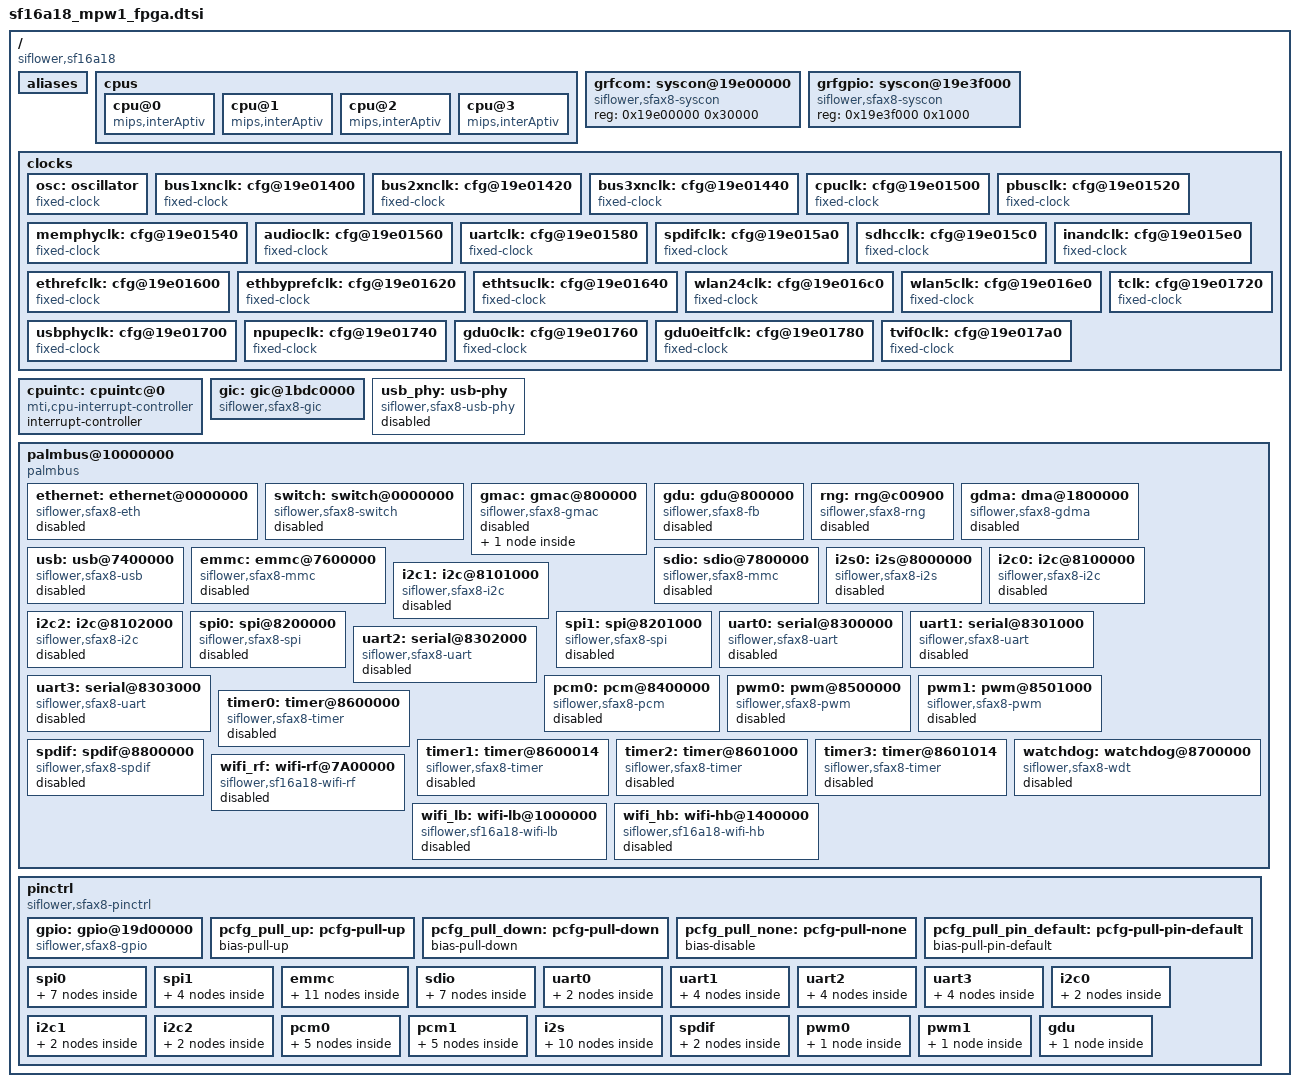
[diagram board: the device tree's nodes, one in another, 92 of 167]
/*
 * This program is free software; you can redistribute it and/or modify
 * it under the terms of the GNU General Public License as published by
 * the Free Software Foundation; either version 2 of the License, or
 * (at your option) any later version.
 *
 * This program is distributed in the hope that it will be useful,
 * but WITHOUT ANY WARRANTY; without even the implied warranty of
 * MERCHANTABILITY or FITNESS FOR A PARTICULAR PURPOSE.  See the
 * GNU General Public License for more details.
 */


/ {
	compatible = "siflower,sf16a18";

	aliases {
		gdu = &gdu;
		gdma = &gdma;
		usb = &usb;
		emmc = &emmc;
		sdio = &sdio;
		i2s = &i2s0;
		i2c0 = &i2c0;
		i2c1 = &i2c1;
		i2c2 = &i2c2;
		spi0 = &spi0;
		spi1 = &spi1;
		uart0=&uart0;
		uart1=&uart1;
		uart2=&uart2;
		uart3=&uart3;
		pcm0 = &pcm0;
		/*pcm1 = &pcm1;*/
		pwm0 = &pwm0;
		pwm1 = &pwm1;
		timer0 = &timer0;
		timer1 = &timer1;
		timer2 = &timer2;
		timer3 = &timer3;
		watchdog = &watchdog;
		spdif = &spdif;
	};

	cpus{
		cpu@0 {
			compatible = "mips,interAptiv";
		};
		cpu@1 {
			compatible = "mips,interAptiv";
		};
		cpu@2 {
			compatible = "mips,interAptiv";
		};
		cpu@3 {
			compatible = "mips,interAptiv";
		};
	};

	grfcom: syscon@19e00000 {
			compatible = "siflower,sfax8-syscon";
			reg = <0x19e00000 0x30000>;
		};

	grfgpio: syscon@19e3f000 {
			compatible = "siflower,sfax8-syscon";
			reg = <0x19e3f000 0x1000>;
		};

	clocks{
		#address-cells = <1>;
		#size-cells = <1>;
		ranges;

		osc: oscillator {
			compatible = "fixed-clock";
			#clock-cells = <0>;
			clock-frequency  = <12000000>;
			clock-output-names = "osc";
		};

		bus1xnclk: cfg@19e01400 {
			compatible = "fixed-clock";
			#clock-cells = <0>;
			clock-frequency  = <50000000>;
			clock-output-names = "bus1xnclk";
		};

		bus2xnclk: cfg@19e01420 {
			compatible = "fixed-clock";
			#clock-cells = <0>;
			clock-frequency  = <50000000>;
			clock-output-names = "bus2xnclk";
		};

		bus3xnclk: cfg@19e01440 {
			compatible = "fixed-clock";
			#clock-cells = <0>;
			clock-frequency  = <80000000>;
			clock-output-names = "bus3xnclk";
		};

		cpuclk: cfg@19e01500 {
			compatible = "fixed-clock";
			#clock-cells = <0>;
			clock-frequency  = <40000000>;
			clock-output-names = "cpuclk";
		};

		pbusclk: cfg@19e01520 {
			compatible = "fixed-clock";
			#clock-cells = <0>;
			clock-frequency  = <50000000>;
			clock-output-names = "pbusclk";
		};

		memphyclk: cfg@19e01540 {
			compatible = "fixed-clock";
			#clock-cells = <0>;
			clock-frequency  = <140000000>;
			clock-output-names = "memphyclk";
		};

		audioclk: cfg@19e01560 {
			compatible = "fixed-clock";
			#clock-cells = <0>;
			clock-frequency  = <60000000>;
			clock-output-names = "audioclk";
		};

		uartclk: cfg@19e01580 {
			compatible = "fixed-clock";
			#clock-cells = <0>;
			clock-frequency  = <60000000>;
			clock-output-names = "uartclk";
		};

		spdifclk: cfg@19e015a0 {
			compatible = "fixed-clock";
			#clock-cells = <0>;
			clock-frequency  = <60000000>;
			clock-output-names = "spdifclk";
		};

		sdhcclk: cfg@19e015c0 {
			compatible = "fixed-clock";
			#clock-cells = <0>;
			clock-frequency  = <50000000>;
			clock-output-names = "sdhcclk";
		};

		inandclk: cfg@19e015e0 {
			compatible = "fixed-clock";
			#clock-cells = <0>;
			clock-frequency  = <50000000>;
			clock-output-names = "inandclk";
		};

		ethrefclk: cfg@19e01600 {
			compatible = "fixed-clock";
			#clock-cells = <0>;
			clock-frequency  = <25000000>;
			clock-output-names = "ethrefclk";
		};

		ethbyprefclk: cfg@19e01620 {
			compatible = "fixed-clock";
			#clock-cells = <0>;
			clock-frequency  = <125000000>;
			clock-output-names = "ethbyprefclk";
		};

		ethtsuclk: cfg@19e01640 {
			compatible = "fixed-clock";
			#clock-cells = <0>;
			clock-frequency  = <25000000>;
			clock-output-names = "ethtsuclk";
		};

		wlan24clk: cfg@19e016c0 {
			compatible = "fixed-clock";
			#clock-cells = <0>;
			clock-frequency  = <30000000>;
			clock-output-names = "wlan24clk";
		};

		wlan5clk: cfg@19e016e0 {
			compatible = "fixed-clock";
			#clock-cells = <0>;
			clock-frequency  = <30000000>;
			clock-output-names = "wlan5clk";
		};

		usbphyclk: cfg@19e01700 {
			compatible = "fixed-clock";
			#clock-cells = <0>;
			clock-frequency  = <50000000>;
			clock-output-names = "usbphyclk";
		};

		tclk: cfg@19e01720 {
			compatible = "fixed-clock";
			#clock-cells = <0>;
			clock-frequency  = <50000000>;
			clock-output-names = "tclk";
		};

		npupeclk: cfg@19e01740 {
			compatible = "fixed-clock";
			#clock-cells = <0>;
			clock-frequency  = <500000000>;
			clock-output-names = "npupeclk";
		};

		gdu0clk: cfg@19e01760 {
			compatible = "fixed-clock";
			#clock-cells = <0>;
			clock-frequency  = <198000000>;
			clock-output-names = "gdu0clk";
		};

		gdu0eitfclk: cfg@19e01780 {
			compatible = "fixed-clock";
			#clock-cells = <0>;
			clock-frequency  = <40000000>;
			clock-output-names = "gdu0eitfclk";
		};

		tvif0clk: cfg@19e017a0 {
			compatible = "fixed-clock";
			#clock-cells = <0>;
			clock-frequency  = <198000000>;
			clock-output-names = "tvif0clk";
		};

	};
	cpuintc: cpuintc@0 {
		compatible = "mti,cpu-interrupt-controller";
		#address-cells = <0>;
		#interrupt-cells = <1>;
		interrupt-controller;
	};

	gic: gic@1bdc0000 {
		#interrupt-cells = <2>;
		interrupt-controller;
		compatible = "siflower,sfax8-gic";
		reg = <0x1bdc0000 0x20000>;/*gic*/
		clocks = <&cpuclk 0>;
	};

	usb_phy: usb-phy {
		compatible = "siflower,sfax8-usb-phy";
		clocks = <&usbphyclk 0>;
		usbgrf = <&grfcom>;
		#phy-cells = <0>;
		status = "disabled";
	};

	palmbus@10000000 {
		compatible = "palmbus";
		reg = <0x10000000 0x10000000>;
		ranges = <0x0 0x10000000 0xFFFFFFF>;
		#address-cells = <1>;
		#size-cells = <1>;
		interrupt-parent = <&gic>;

		ethernet: ethernet@0000000 {
			compatible = "siflower,sfax8-eth";
			reg = <0x0000000 0x6CFFFF>;
			clocks = <&ethrefclk 0>, <&ethbyprefclk 0>, <&ethtsuclk 0>;
			mtd-mac-address = <&factory 0>;
			interrupts = <16 0>;
			status = "disabled";
		};

		switch: switch@0000000 {
			compatible = "siflower,sfax8-switch";
			reg = <0x0000000 0x6CFFFF>;
			interrupts = <25 0>;
			max-speed = <100>;
			sfax8,port-map = "llllw";
			status = "disabled";
		};

		gmac: gmac@800000 {
			compatible = "siflower,sfax8-gmac";
			reg = <0x800000 0x200000>;
			clocks = <&ethbyprefclk 0>, <&ethtsuclk 0>;
			interrupts = <32 0>;

			mac-address = [ 00 11 22 33 44 55 ];
			phy = <&phy0>;

			#address-cells = <1>;
			#size-cells = <0>;
			status = "disabled";

			phy0: ethernet-phy@0 {
				reg = <1>;
				max-speed = <1000>;
			};
		};

		gdu: gdu@800000 {
			compatible = "siflower,sfax8-fb";
			reg = <0x800000 0x10000>;
			interrupts = <39 0>;
			status = "disabled";
			clocks = <&gdu0eitfclk 0>;
			pinctrl-names = "default";
			pinctrl-0 = <&gdu_0>;
		};

		rng: rng@c00900 {
			compatible = "siflower,sfax8-rng";
			reg = <0xc00900 0x28>;
			rnggrf = <&grfcom>;
			status = "disabled";
		};

		gdma: dma@1800000 {
			compatible = "siflower,sfax8-gdma";
			reg = <0x1800000 0x1000>;
			interrupts = <80 0>;
			#dma-cells = <1>;
			#dma-channels = <7>;
			#dma-requests = <32>;
			status = "disabled";
		};

		usb: usb@7400000 {
			compatible = "siflower,sfax8-usb";
			reg = <0x7400000 0x40000>;
			interrupts = <128 0>;
			clocks = <&usbphyclk 0>;
			dr_mode = "otg";
			phys = <&usb_phy>;
			phy-names = "usb2-phy";
			usbgrf = <&grfcom>;
			status = "disabled";

			g-use-dma;
			g-tx-fifo-size = <0x100 0x100 0x100 0x100 0x100
				0x300 0x300 0x300>;
		};

		emmc: emmc@7600000 {
			compatible = "siflower,sfax8-mmc";
			reg = <0x7600000 0x200000>;
			clocks = <&inandclk 0>;
			clock-freq-min-max = <400000 50000000>;
			fifo-depth = <0x200>;
			bus-width = <8>;
			interrupts = <144 0>;
			read-delayline = <15>;
			write-delayline = <15>;
			supports-highspeed;
			pinctrl-names = "default";
			pinctrl-0 = <&emmc_data0 &emmc_data1 &emmc_data2 &emmc_data3 \
						 &emmc_data4 &emmc_data5 &emmc_data6 &emmc_data7 \
						 &emm_clk &emmc_cmd &emmc_resetn>;
			status = "disabled";
		};

		sdio: sdio@7800000 {
			compatible = "siflower,sfax8-mmc";
			reg = <0x7800000 0x200000>;
			clocks = <&sdhcclk 0>;
			/*clock-names = "biu", "ciu";*/
			bus-width = <4>;
			read-delayline = <15>;
			write-delayline = <15>;
			interrupts = <160 0>;
			pinctrl-names = "default";
			pinctrl-0 = <&sdio_data0 &sdio_data1 &sdio_data2 &sdio_data3 \
						 &sdi_clk &sdio_cmd &sdio_cd>;
			status = "disabled";
		};

		i2s0: i2s@8000000 {
			compatible = "siflower,sfax8-i2s";
			interrupts = <208 0>;
			reg = <0x8000000 0x1000>;
			clocks = <&audioclk 0>;
			dmas = <&gdma 0
			&gdma 1>;
			dma-names = "tx", "rx";
			pinctrl-names = "default";
			pinctrl-0 = <&i2s0_cdclk &i2s0_sclk &i2s0_lrck &i2s0_sdi0 &i2s0_sdo0>;
			status = "disabled";
		};

		i2c0: i2c@8100000 {
			compatible = "siflower,sfax8-i2c";
			reg = <0x8100000 0x1000>;
			clocks = <&pbusclk 0>;
			clock-frequency = <400000>;
			interrupts = <217 0>;
			#address-cells = <1>;
			#size-cells = <0>;
			pinctrl-names="default";
			pinctrl-0 = <&i2c0_clk &i2c0_dat>;
			status = "disabled";
		};

		i2c1: i2c@8101000 {
			compatible = "siflower,sfax8-i2c";
			reg = <0x8101000 0x1000>;
			clocks = <&pbusclk 0>;
			clock-frequency = <400000>;
			interrupts = <218 0>;
			#address-cells = <1>;
			#size-cells = <0>;
			pinctrl-names="default";
			pinctrl-0 = <&i2c1_clk &i2c1_dat>;
			status = "disabled";
		};

		i2c2: i2c@8102000 {
			compatible = "siflower,sfax8-i2c";
			reg = <0x8102000 0x1000>;
			clocks = <&pbusclk 0>;
			clock-frequency = <400000>;
			interrupts = <219 0>;
			status = "disabled";
		};

		spi0: spi@8200000 {
			compatible = "siflower,sfax8-spi";
			reg = <0x8200000 0x1000>;
			num-cs = <2>;
			cs-gpios = <&gpio 5 0>, <&gpio 6 0>;
			spi-max-frequency = <33000000>;

			clocks = <&pbusclk 0>;
			sfgrf = <&grfcom>;

			interrupt-parent = <&gic>;
			interrupts = <223 0>;

			use-dma;
			dmas = <&gdma 10
				&gdma 11>;
			dma-names = "tx", "rx";

			#address-cells = <1>;
			#size-cells = <0>;
			status = "disabled";
		};

		spi1: spi@8201000 {
			compatible = "siflower,sfax8-spi";
			reg = <0x8201000 0x1000>;
			clocks = <&pbusclk 0>;
			status = "disabled";

			num-cs = <1>;
			/*cs-gpios = <&gpio 34 0>;*/
			spi-max-frequency = <33000000>;
			sfgrf = <&grfcom>;

			interrupt-parent = <&gic>;
			interrupts = <224 0>;

		/*	use-dma;
			dmas = <&gdma 12
				&gdma 13>;
			dma-names = "tx", "rx";
		*/
			#address-cells = <1>;
			#size-cells = <0>;
		};

		uart0: serial@8300000 {
			compatible = "siflower,sfax8-uart";
			reg = <0x8300000 0x1000>;
			interrupts = <226 0>;
			clocks = <&uartclk 0>;
			status = "disabled";
		};

		uart1: serial@8301000 {
			compatible = "siflower,sfax8-uart";
			reg = <0x8301000 0x1000>;
			interrupts = <227 0>;
			clocks = <&uartclk 0>;
			dmas = <&gdma 14
			&gdma 15>;
			dma-names = "tx", "rx";
			status = "disabled";
		};

		uart2: serial@8302000 {
			compatible = "siflower,sfax8-uart";
			reg = <0x8302000 0x1000>;
			clocks = <&uartclk 0>;
			interrupts = <228 0>;
			status = "disabled";
		};

		uart3: serial@8303000 {
			compatible = "siflower,sfax8-uart";
			reg = <0x8303000 0x1000>;
			clocks = <&uartclk 0>;
			interrupts = <229 0>;
			status = "disabled";
		};

		pcm0: pcm@8400000 {
			compatible = "siflower,sfax8-pcm";
			reg = <0x8400000 0x1000>;
			clocks =<&audioclk 0>;
			id = <0>;
			dmas = <&gdma 20
				&gdma 21>;
			dma-names = "tx","rx";
			interrupts = <230 0>;
			pinctrl-names = "default";
			pinctrl-0 = <&pcm0_cdclk &pcm0_sclk &pcm0_fsync &pcm0_sin &pcm0_sout>;
			status = "disabled";
		};

		/*
		pcm1: pcm@8401000 {
			compatible = "siflower,sfax8-pcm";
			reg = <0x8401000 0x1000>;
			clocks =<&audioclk 0>;
			id = <1>;
			dmas = <&gdma 22
				&gdma 23>;
			dma-names = "tx","rx";
			interrupts = <231 0>;

			pinctrl-names = "default";
			pinctrl-0 = <&pcm1_cdclk &pcm1_sclk &pcm1_fsync &pcm1_sin &pcm1_sout>;
		};
		*/

		pwm0: pwm@8500000 {
			compatible = "siflower,sfax8-pwm";
			reg = <0x8500000 0x1000>;
			interrupts = <232 0>;
			clocks = <&pbusclk 0>;
			pwm-outputs = <0>;
			pinctrl-names = "default";
			pinctrl-0 = <&pwm_0>; //36
			status = "disabled";
		};

		pwm1: pwm@8501000 {
			compatible = "siflower,sfax8-pwm";
			reg = <0x8501000 0x1000>;
			interrupts = <233 0>;
			clocks = <&pbusclk 0>;
			pwm-outputs = <0>;

			pinctrl-names = "default";
			pinctrl-0 = <&pwm_1>; //37
			status = "disabled";
		};

		timer0: timer@8600000 {
			compatible = "siflower,sfax8-timer";
			reg = <0x8600000 0x14>;
			interrupts = <234 0>;
			clocks = <&pbusclk 0>;
			clock-names = "timer";
			status = "disabled";
		};

		timer1: timer@8600014 {
			compatible = "siflower,sfax8-timer";
			reg = <0x8600014 0x14>;
			interrupts = <235 0>;
			clocks = <&pbusclk 0>;
			clock-names = "timer";
			status = "disabled";
		};

		timer2: timer@8601000 {
			compatible = "siflower,sfax8-timer";
			reg = <0x8601000 0x14>;
			interrupts = <236 0>;
			clocks = <&pbusclk 0>;
			clock-names = "timer";
			status = "disabled";
		};

		timer3: timer@8601014 {
			compatible = "siflower,sfax8-timer";
			reg = <0x8601014 0x14>;
			interrupts = <237 0>;
			clocks = <&pbusclk 0>;
			clock-names = "timer";
			status = "disabled";
		};

		watchdog: watchdog@8700000 {
			compatible = "siflower,sfax8-wdt";
			reg = <0x8700000 0x1000>;
			interrupt-parent = <&gic>;
			interrupts = <238 0>;
			clocks = <&pbusclk 0>;
			status = "disabled";
		};

		spdif: spdif@8800000 {
			compatible = "siflower,sfax8-spdif";
			reg = <0x8800000 0x1000>;
			interrupts = <239 0>;
			clocks = <&spdifclk 0>;
			dmas = <&gdma 8
				&gdma 9>;
			dma-names = "tx", "rx";
			status = "disabled";
		};

		wifi_rf: wifi-rf@7A00000{
			compatible = "siflower,sf16a18-wifi-rf";
			reg = <0x7A00000 0x600000>;
			interrupts = <176 0>;
			status = "disabled";
		};

		wifi_lb: wifi-lb@1000000{
			compatible = "siflower,sf16a18-wifi-lb";
			reg = <0x1000000 0x400000>;
			interrupts = <48 0>, <49 0>;
			mtd-mac-address = <&factory 0>;
			clocks = <&wlan24clk 0>;
			status = "disabled";
		};

		wifi_hb: wifi-hb@1400000{
			compatible = "siflower,sf16a18-wifi-hb";
			reg = <0x1400000 0x400000>;
			interrupts = <64 0>, <65 0>;
			mtd-mac-address = <&factory 0>;
			clocks = <&wlan5clk 0>;
			status = "disabled";
		};

	}; /* palmbus */

	pinctrl: pinctrl {
		compatible = "siflower,sfax8-pinctrl";
		#address-cells = <1>;
		#size-cells = <1>;
		interrupt-parent = <&gic>;
		ranges;
		pad-base = <&grfgpio>;

		gpio: gpio@19d00000 {
			compatible = "siflower,sfax8-gpio";
			reg=<0x19d00000 0x100000>;
			interrupts = <246 0>, <247 0>, <248 0>, <249 0>;
			clocks = <&pbusclk 0>;

			gpio-controller;
			#gpio-cells = <2>;

			interrupt-controller;
			#interrupt-cells = <2>;
		};

		pcfg_pull_up: pcfg-pull-up {
			bias-pull-up;
		};

		pcfg_pull_down: pcfg-pull-down {
			bias-pull-down;
		};

		pcfg_pull_none: pcfg-pull-none {
			bias-disable;
		};

		pcfg_pull_pin_default: pcfg-pull-pin-default {
			bias-pull-pin-default;
		};


		spi0 {
			spi0_mosi: spi0-mosi {
				sfax8,pins = <0 0 1 &pcfg_pull_pin_default>;
			};
			spi0_miso: spi0-miso {
				sfax8,pins = <0 1 1 &pcfg_pull_pin_default>;
			};
			spi0_hold: spi0-hold {
				sfax8,pins = <0 2 1 &pcfg_pull_pin_default>;
			};
			spi0_wp: spi0-wp {
				sfax8,pins = <0 3 1 &pcfg_pull_pin_default>;
			};
			spi0_clk: spi0-clk {
				sfax8,pins = <0 4 1 &pcfg_pull_pin_default>;
			};
			spi0_cs0: spi0-cs0 {
				sfax8,pins = <0 5 1 &pcfg_pull_pin_default>;
			};
			spi0_cs1: spi0-cs1 {
				sfax8,pins = <0 6 1 &pcfg_pull_pin_default>;
			};
		};

		spi1 {
			spi1_txd: spi1-txd {
				sfax8,pins = <0 31 1 &pcfg_pull_pin_default>;
			};
			spi1_rxd: spi1-rxd {
				sfax8,pins = <0 32 1 &pcfg_pull_pin_default>;
			};
			spi1_clk: spi1-clk {
				sfax8,pins = <0 33 1 &pcfg_pull_pin_default>;
			};
			spi1_csn: spi1-csn {
				sfax8,pins = <0 34 1 &pcfg_pull_pin_default>;
			};
		};


		emmc {
			emmc_data0: emmc-data0 {
				sfax8,pins = <0 0 0 &pcfg_pull_pin_default>;
			};

			emmc_data1: emmc-data1 {
				sfax8,pins = <0 1 0 &pcfg_pull_pin_default>;
			};

			emmc_data2: emmc-data2 {
				sfax8,pins = <0 2 0 &pcfg_pull_pin_default>;
			};

			emmc_data3: emmc-data3 {
				sfax8,pins = <0 3 0 &pcfg_pull_pin_default>;
			};

			emmc_data4: emmc-data4 {
				sfax8,pins = <0 4 0 &pcfg_pull_pin_default>;
			};

			emmc_data5: emmc-data5 {
				sfax8,pins = <0 8 0 &pcfg_pull_pin_default>;
			};

			emmc_data6: emmc-data6 {
				sfax8,pins = <0 9 0 &pcfg_pull_pin_default>;
			};

			emmc_data7: emmc-data7 {
				sfax8,pins = <0 10 0 &pcfg_pull_pin_default>;
			};

			emm_clk: emmc-clk {
				sfax8,pins = <0 5 0 &pcfg_pull_pin_default>;
			};

			emmc_cmd: emmc-cmd {
				sfax8,pins = <0 6 0 &pcfg_pull_pin_default>;
			};

			emmc_resetn: emmc-resetn {
				sfax8,pins = <0 7 0 &pcfg_pull_pin_default>;
			};
		};

		sdio {
			sdio_data0: sdio-data0 {
				sfax8,pins = <0 11 0 &pcfg_pull_pin_default>;
			};

			sdio_data1: sdio-data1 {
				sfax8,pins = <0 12 0 &pcfg_pull_pin_default>;
			};

			sdio_data2: sdio-data2 {
				sfax8,pins = <0 13 0 &pcfg_pull_pin_default>;
			};

			sdio_data3: sdio-data3 {
				sfax8,pins = <0 14 0 &pcfg_pull_pin_default>;
			};
			sdi_clk: sdio-clk {
				sfax8,pins = <0 15 0 &pcfg_pull_pin_default>;
			};

			sdio_cmd: sdio-cmd {
				sfax8,pins = <0 16 0 &pcfg_pull_pin_default>;
			};

			sdio_cd: sdio-cd {
				sfax8,pins = <0 17 0 &pcfg_pull_pin_default>;
			};
		};

		uart0 {
			uart0_tx: uart0-tx {
				sfax8,pins = <0 18 0 &pcfg_pull_pin_default>;
			};

			uart0_rx: uart0-rx {
				sfax8,pins = <0 19 0 &pcfg_pull_pin_default>;
			};
		};

		uart1 {
			uart1_tx: uart1-tx {
				sfax8,pins = <0 26 2 &pcfg_pull_pin_default>;
			};

			uart1_rx: uart1-rx {
				sfax8,pins = <0 27 2 &pcfg_pull_pin_default>;
			};

			uart1_cts: uart1-cts {
				sfax8,pins = <0 30 2 &pcfg_pull_pin_default>;
			};

			uart1_rts: uart1-rts {
				sfax8,pins = <0 29 2 &pcfg_pull_pin_default>;
			};

		};

		uart2 {
			uart2_tx: uart2-tx {
				sfax8,pins = <0 22 2 &pcfg_pull_pin_default>;
			};

			uart2_rx: uart2-rx {
				sfax8,pins = <0 23 2 &pcfg_pull_pin_default>;
			};

			uart2_cts: uart2-cts {
				sfax8,pins = <0 24 2 &pcfg_pull_pin_default>;
			};

			uart2_rts: uart2-rts {
				sfax8,pins = <0 25 2 &pcfg_pull_pin_default>;
			};
		};

		uart3 {
			uart3_tx: uart3-tx {
				sfax8,pins = <0 32 2 &pcfg_pull_pin_default>;
			};

			uart3_rx: uart3-rx {
				sfax8,pins = <0 31 2 &pcfg_pull_pin_default>;
			};

			uart3_cts: uart3-cts {
				sfax8,pins = <0 35 2 &pcfg_pull_pin_default>;
			};

			uart3_rts: uart3-rts {
				sfax8,pins = <0 34 2 &pcfg_pull_pin_default>;
			};
		};

		i2c0 {
			i2c0_clk: i2c0-clk {
				sfax8,pins = <0 20 0 &pcfg_pull_pin_default>;
			};

			i2c0_dat: i2c0-dat {
				sfax8,pins = <0 21 0 &pcfg_pull_pin_default>;
			};
		};

		i2c1 {
			i2c1_clk: i2c1-clk {
				sfax8,pins = <0 22 0 &pcfg_pull_pin_default>;
			};

			i2c1_dat: i2c1-dat {
				sfax8,pins = <0 23 0 &pcfg_pull_pin_default>;
			};
		};

		i2c2 {
			i2c2_clk: i2c2-clk {
				sfax8,pins = <0 24 0 &pcfg_pull_pin_default>;
			};

			i2c2_dat: i2c2-dat {
				sfax8,pins = <0 25 0 &pcfg_pull_pin_default>;
			};
		};

		pcm0 {
			pcm0_cdclk: pcm0-cdclk {
				sfax8,pins = <0 26 1 &pcfg_pull_pin_default>;
			};

			pcm0_sclk: pcm0-sclk {
				sfax8,pins = <0 27 1 &pcfg_pull_pin_default>;
			};

			pcm0_fsync: pcm0-fsync {
				sfax8,pins = <0 28 1 &pcfg_pull_pin_default>;
			};

			pcm0_sin: pcm0-sin {
				sfax8,pins = <0 29 1 &pcfg_pull_pin_default>;
			};

			pcm0_sout: pcm0-sout {
				sfax8,pins = <0 30 1 &pcfg_pull_pin_default>;
			};
		};

		pcm1 {
			pcm1_cdclk: pcm1-cdclk {
				sfax8,pins = <0 22 1 &pcfg_pull_pin_default>;
			};

			pcm1_sclk: pcm1-sclk {
				sfax8,pins = <0 23 1 &pcfg_pull_pin_default>;
			};

			pcm1_fsync: pcm1-fsync {
				sfax8,pins = <0 24 1 &pcfg_pull_pin_default>;
			};

			pcm1_sin: pcm1-sin {
				sfax8,pins = <0 25 1 &pcfg_pull_pin_default>;
			};

			pcm1_sout: pcm1-sout {
				sfax8,pins = <0 36 1 &pcfg_pull_pin_default>;
			};
		};

		i2s {
			i2s0_cdclk: i2s0-cdclk {
				sfax8,pins = <0 26 0 &pcfg_pull_pin_default>;
			};

			i2s0_sclk: i2s0-sclk {
				sfax8,pins = <0 27 0 &pcfg_pull_pin_default>;
			};

			i2s0_lrck: i2s0-lrck {
				sfax8,pins = <0 28 0 &pcfg_pull_pin_default>;
			};

			i2s0_sdi0: i2s0-sdi0 {
				sfax8,pins = <0 29 0 &pcfg_pull_pin_default>;
			};

			i2s0_sdo0: i2s0-sdo0 {
				sfax8,pins = <0 30 0 &pcfg_pull_pin_default>;
			};

			i2s1_cdclk: i2s1-cdclk {
				sfax8,pins = <0 31 0 &pcfg_pull_pin_default>;
			};

			i2s1_sclk: i2s1-sclk {
				sfax8,pins = <0 32 0 &pcfg_pull_pin_default>;
			};

			i2s1_lrck: i2s1-lrck {
				sfax8,pins = <0 33 0 &pcfg_pull_pin_default>;
			};

			i2s1_sdi0: i2s1-sdi0 {
				sfax8,pins = <0 34 0 &pcfg_pull_pin_default>;
			};

			i2s1_sdo0: i2s1-sdo0 {
				sfax8,pins = <0 35 0 &pcfg_pull_pin_default>;
			};
		};

		spdif {
			spdif_0: spdif-0 {
				sfax8,pins = <0 35 0 &pcfg_pull_pin_default>;
			};

			spdif_1: spdif-1 {
				sfax8,pins = <0 62 0 &pcfg_pull_pin_default>;
			};
		};

		pwm0 {
			pwm_0: pwm-0 {
				sfax8,pins = <0 36 0 &pcfg_pull_pin_default>;
			};
		};

		pwm1 {
			pwm_1: pwm-1 {
				sfax8,pins = <0 37 0 &pcfg_pull_pin_default>;
			};
		};

		gdu {
			gdu_0: gdu-0 {
				sfax8,pins = <0 11 3 &pcfg_pull_pin_default>,
					<0 12 3 &pcfg_pull_pin_default>,
					<0 13 3 &pcfg_pull_pin_default>,
					<0 14 3 &pcfg_pull_pin_default>,
					<0 24 3 &pcfg_pull_pin_default>,
					<0 25 3 &pcfg_pull_pin_default>,
					<0 31 3 &pcfg_pull_pin_default>,
					<0 32 3 &pcfg_pull_pin_default>,
					<0 33 3 &pcfg_pull_pin_default>,
					<0 34 3 &pcfg_pull_pin_default>,
					<0 35 3 &pcfg_pull_pin_default>,
					<0 38 3 &pcfg_pull_pin_default>,
					<0 39 3 &pcfg_pull_pin_default>,
					<0 40 3 &pcfg_pull_pin_default>,
					<0 41 3 &pcfg_pull_pin_default>,
					<0 42 3 &pcfg_pull_pin_default>,
					<0 43 3 &pcfg_pull_pin_default>,
					<0 44 3 &pcfg_pull_pin_default>,
					<0 45 3 &pcfg_pull_pin_default>,
					<0 46 3 &pcfg_pull_pin_default>,
					<0 47 3 &pcfg_pull_pin_default>,
					<0 48 3 &pcfg_pull_pin_default>,
					<0 49 3 &pcfg_pull_pin_default>,
					<0 50 3 &pcfg_pull_pin_default>,
					<0 51 3 &pcfg_pull_pin_default>,
					<0 52 3 &pcfg_pull_pin_default>,
					<0 53 3 &pcfg_pull_pin_default>,
					<0 54 3 &pcfg_pull_pin_default>;
			};
		};

	};
};
